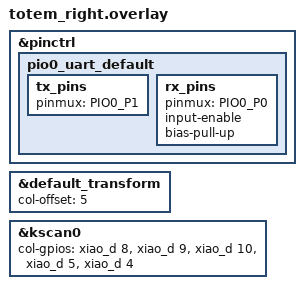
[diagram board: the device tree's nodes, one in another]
/*
 * Copyright (c) 2022 The ZMK Contributors
 *
 * SPDX-License-Identifier: MIT
 */

#include "totem.dtsi"
#include <dt-bindings/pinctrl/rpi-pico-rp2040-pinctrl.h>

&pinctrl {
    pio0_uart_default: pio0_uart_default {
        tx_pins {
            /* configure P1 as UART0 TX */
            pinmux = <PIO0_P1>;
            };
        rx_pins {
            /* configure P0 as UART0 RX */
            pinmux = <PIO0_P0>;
            input-enable;
            bias-pull-up;
        };
    };
};

&default_transform {
    col-offset = <5>;
};

&kscan0 {
    col-gpios
        = <&xiao_d 8 GPIO_ACTIVE_HIGH>
        , <&xiao_d 9 GPIO_ACTIVE_HIGH>
        , <&xiao_d 10 GPIO_ACTIVE_HIGH>
        , <&xiao_d 5 GPIO_ACTIVE_HIGH>
        , <&xiao_d 4 GPIO_ACTIVE_HIGH>
        ;
};
